VERSION ""

NS_ :

BS_:

BU_: XXX

BO_ 3 NEW_MSG_1: 8 XXX
 SG_ STEERING_ANGLE : 7|32@0- (1,0) [0|4294967295] "" XXX
 SG_ NEW_SIGNAL_1 : 55|8@0+ (1,0) [0|255] "" XXX

BO_ 5 NEW_MSG_2: 8 XXX
 SG_ BRAKE_POSITION : 23|16@0+ (1,0) [0|65535] "" XXX
 SG_ BRAKE_PRESSED : 0|8@1+ (1,0) [0|17] "" XXX

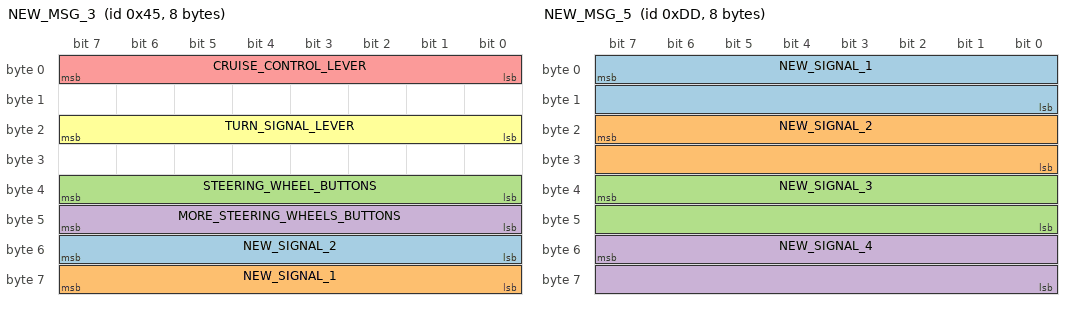
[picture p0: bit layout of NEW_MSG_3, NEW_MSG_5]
BO_ 69 NEW_MSG_3: 8 XXX
 SG_ NEW_SIGNAL_2 : 55|8@0+ (1,0) [0|255] "" XXX
 SG_ NEW_SIGNAL_1 : 63|8@0+ (1,0) [0|255] "" XXX
 SG_ STEERING_WHEEL_BUTTONS : 32|8@1+ (1,0) [0|255] "4 directional, 2 volume control, & 2 phone buttons" XXX
 SG_ MORE_STEERING_WHEELS_BUTTONS : 40|8@1+ (1,0) [0|255] "" XXX
 SG_ CRUISE_CONTROL_LEVER : 7|8@0+ (1,0) [0|255] "" XXX
 SG_ TURN_SIGNAL_LEVER : 16|8@1+ (1,0) [0|255] "" XXX

BO_ 1 NEW_MSG_4: 8 XXX
 SG_ DOOR_LOCK_STATUS : 31|16@0+ (1,0) [0|65535] "" XXX

BO_ 221 NEW_MSG_5: 8 XXX
 SG_ NEW_SIGNAL_1 : 7|16@0+ (1,0) [0|65535] "" XXX
 SG_ NEW_SIGNAL_2 : 23|16@0+ (1,0) [0|65535] "" XXX
 SG_ NEW_SIGNAL_3 : 39|16@0+ (1,0) [0|65535] "" XXX
 SG_ NEW_SIGNAL_4 : 55|16@0+ (1,0) [0|65535] "" XXX

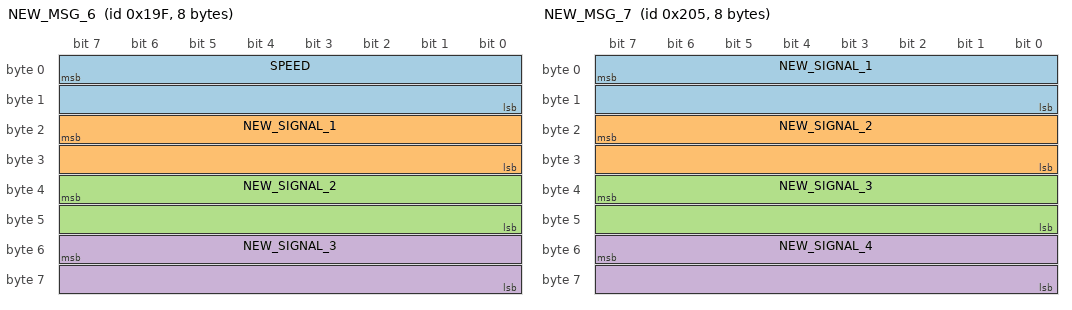
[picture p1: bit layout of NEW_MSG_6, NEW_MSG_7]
BO_ 415 NEW_MSG_6: 8 XXX
 SG_ SPEED : 7|16@0+ (1,0) [0|65535] "kph" XXX
 SG_ NEW_SIGNAL_1 : 23|16@0+ (1,0) [0|65535] "" XXX
 SG_ NEW_SIGNAL_2 : 39|16@0+ (1,0) [0|65535] "" XXX
 SG_ NEW_SIGNAL_3 : 55|16@0+ (1,0) [0|65535] "" XXX

BO_ 517 NEW_MSG_7: 8 XXX
 SG_ NEW_SIGNAL_1 : 7|16@0+ (1,0) [0|65535] "" XXX
 SG_ NEW_SIGNAL_2 : 23|16@0+ (1,0) [0|65535] "" XXX
 SG_ NEW_SIGNAL_3 : 39|16@0+ (1,0) [0|65535] "" XXX
 SG_ NEW_SIGNAL_4 : 55|16@0+ (1,0) [0|65535] "" XXX

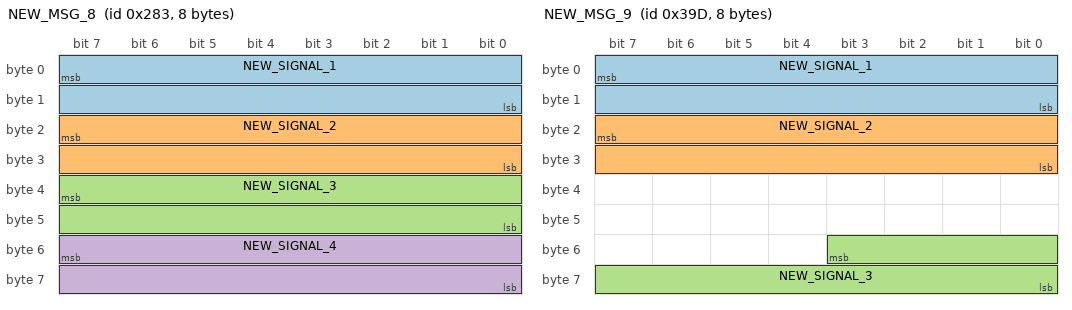
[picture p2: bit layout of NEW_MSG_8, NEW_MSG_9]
BO_ 643 NEW_MSG_8: 8 XXX
 SG_ NEW_SIGNAL_1 : 7|16@0+ (1,0) [0|65535] "" XXX
 SG_ NEW_SIGNAL_2 : 23|16@0+ (1,0) [0|65535] "" XXX
 SG_ NEW_SIGNAL_3 : 39|16@0+ (1,0) [0|65535] "" XXX
 SG_ NEW_SIGNAL_4 : 55|16@0+ (1,0) [0|65535] "" XXX

BO_ 925 NEW_MSG_9: 8 XXX
 SG_ NEW_SIGNAL_1 : 7|16@0+ (1,0) [0|65535] "" XXX
 SG_ NEW_SIGNAL_2 : 23|16@0+ (1,0) [0|65535] "" XXX
 SG_ NEW_SIGNAL_3 : 51|12@0+ (1,0) [0|8191] "" XXX

BO_ 104 NEW_MSG_10: 8 XXX
 SG_ NEW_SIGNAL_1 : 7|8@0+ (1,0) [0|255] "" XXX

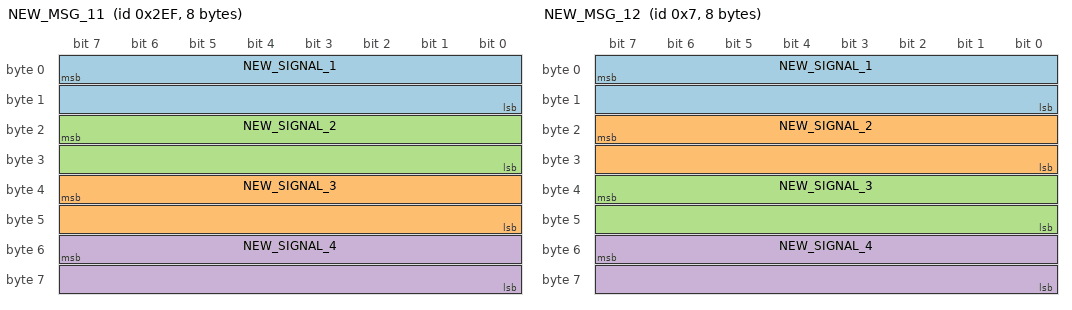
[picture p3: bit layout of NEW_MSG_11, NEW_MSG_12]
BO_ 751 NEW_MSG_11: 8 XXX
 SG_ NEW_SIGNAL_1 : 7|16@0+ (1,0) [0|65535] "" XXX
 SG_ NEW_SIGNAL_3 : 39|16@0+ (1,0) [0|65535] "" XXX
 SG_ NEW_SIGNAL_2 : 23|16@0+ (1,0) [0|65535] "" XXX
 SG_ NEW_SIGNAL_4 : 55|16@0+ (1,0) [0|65535] "" XXX

BO_ 7 NEW_MSG_12: 8 XXX
 SG_ NEW_SIGNAL_1 : 7|16@0+ (1,0) [0|65535] "" XXX
 SG_ NEW_SIGNAL_2 : 23|16@0+ (1,0) [0|65535] "" XXX
 SG_ NEW_SIGNAL_3 : 39|16@0+ (1,0) [0|65535] "" XXX
 SG_ NEW_SIGNAL_4 : 55|16@0+ (1,0) [0|65535] "" XXX

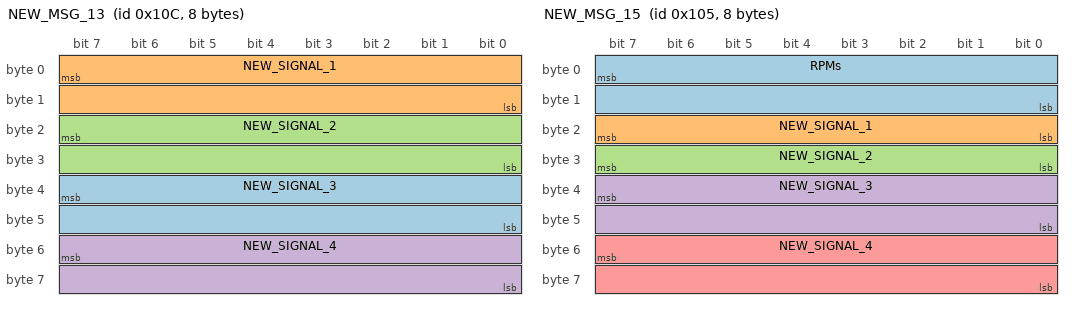
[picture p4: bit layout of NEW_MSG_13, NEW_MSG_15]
BO_ 268 NEW_MSG_13: 8 XXX
 SG_ NEW_SIGNAL_3 : 39|16@0+ (1,0) [0|65535] "" XXX
 SG_ NEW_SIGNAL_1 : 7|16@0+ (1,0) [0|65535] "" XXX
 SG_ NEW_SIGNAL_2 : 23|16@0+ (1,0) [0|65535] "" XXX
 SG_ NEW_SIGNAL_4 : 55|16@0+ (1,0) [0|65535] "" XXX

BO_ 115 NEW_MSG_14: 8 XXX
 SG_ NEW_SIGNAL_1 : 7|8@0+ (1,0) [0|255] "" XXX
 SG_ NEW_SIGNAL_2 : 15|8@0+ (1,0) [0|255] "" XXX
 SG_ NEW_SIGNAL_3 : 48|19@1- (1,0) [0|65535] "" XXX
 SG_ NEW_SIGNAL_4 : 23|16@0+ (1,0) [0|65535] "" XXX
 SG_ NEW_SIGNAL_5 : 39|16@0+ (1,0) [0|65535] "" XXX

BO_ 261 NEW_MSG_15: 8 XXX
 SG_ RPMs : 7|16@0+ (1,0) [0|65535] "" XXX
 SG_ NEW_SIGNAL_1 : 23|8@0+ (1,0) [0|255] "" XXX
 SG_ NEW_SIGNAL_2 : 31|8@0+ (1,0) [0|255] "" XXX
 SG_ NEW_SIGNAL_3 : 39|16@0+ (1,0) [0|65535] "" XXX
 SG_ NEW_SIGNAL_4 : 55|16@0+ (1,0) [0|65535] "" XXX

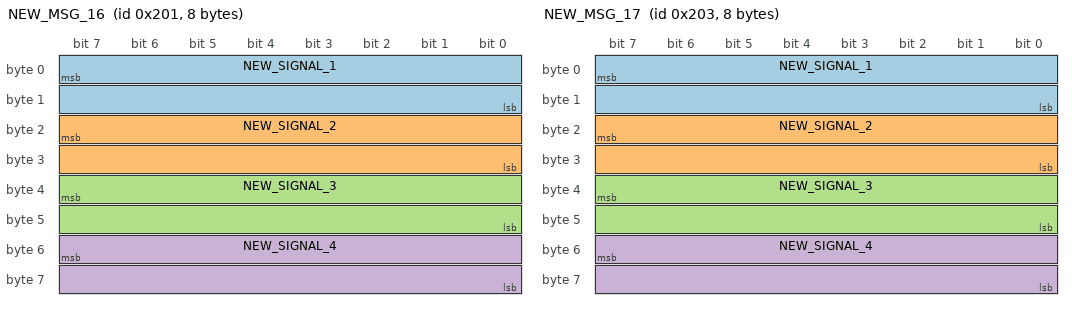
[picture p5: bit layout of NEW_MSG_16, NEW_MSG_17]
BO_ 513 NEW_MSG_16: 8 XXX
 SG_ NEW_SIGNAL_1 : 7|16@0+ (1,0) [0|65535] "" XXX
 SG_ NEW_SIGNAL_2 : 23|16@0+ (1,0) [0|65535] "" XXX
 SG_ NEW_SIGNAL_3 : 39|16@0+ (1,0) [0|65535] "" XXX
 SG_ NEW_SIGNAL_4 : 55|16@0+ (1,0) [0|65535] "" XXX

BO_ 515 NEW_MSG_17: 8 XXX
 SG_ NEW_SIGNAL_1 : 7|16@0+ (1,0) [0|65535] "" XXX
 SG_ NEW_SIGNAL_2 : 23|16@0+ (1,0) [0|65535] "" XXX
 SG_ NEW_SIGNAL_3 : 39|16@0+ (1,0) [0|65535] "" XXX
 SG_ NEW_SIGNAL_4 : 55|16@0+ (1,0) [0|65535] "" XXX

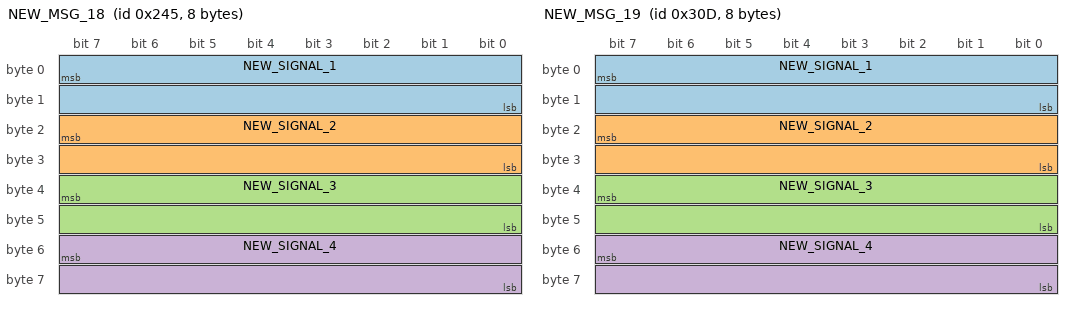
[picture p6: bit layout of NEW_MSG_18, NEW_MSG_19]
BO_ 581 NEW_MSG_18: 8 XXX
 SG_ NEW_SIGNAL_1 : 7|16@0+ (1,0) [0|65535] "" XXX
 SG_ NEW_SIGNAL_2 : 23|16@0+ (1,0) [0|65535] "" XXX
 SG_ NEW_SIGNAL_3 : 39|16@0+ (1,0) [0|65535] "" XXX
 SG_ NEW_SIGNAL_4 : 55|16@0+ (1,0) [0|65535] "" XXX

BO_ 781 NEW_MSG_19: 8 XXX
 SG_ NEW_SIGNAL_1 : 7|16@0+ (1,0) [0|65535] "" XXX
 SG_ NEW_SIGNAL_2 : 23|16@0+ (1,0) [0|65535] "" XXX
 SG_ NEW_SIGNAL_3 : 39|16@0+ (1,0) [0|65535] "" XXX
 SG_ NEW_SIGNAL_4 : 55|16@0+ (1,0) [0|65535] "" XXX

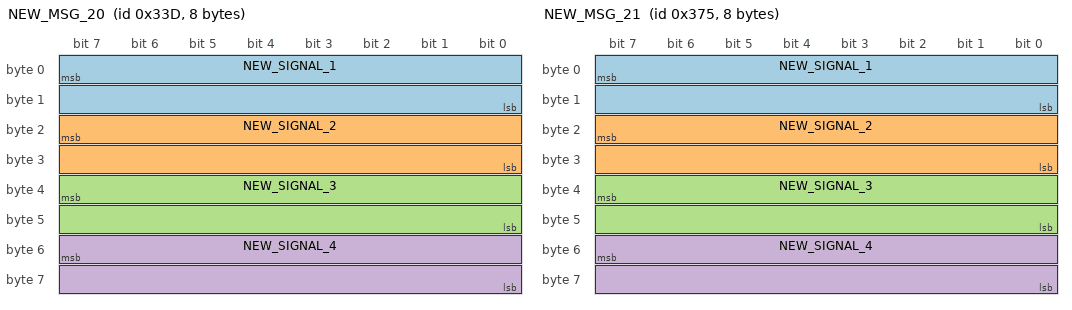
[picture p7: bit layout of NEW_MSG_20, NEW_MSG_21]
BO_ 829 NEW_MSG_20: 8 XXX
 SG_ NEW_SIGNAL_1 : 7|16@0+ (1,0) [0|65535] "" XXX
 SG_ NEW_SIGNAL_2 : 23|16@0+ (1,0) [0|65535] "" XXX
 SG_ NEW_SIGNAL_3 : 39|16@0+ (1,0) [0|65535] "" XXX
 SG_ NEW_SIGNAL_4 : 55|16@0+ (1,0) [0|65535] "" XXX

BO_ 885 NEW_MSG_21: 8 XXX
 SG_ NEW_SIGNAL_1 : 7|16@0+ (1,0) [0|65535] "" XXX
 SG_ NEW_SIGNAL_2 : 23|16@0+ (1,0) [0|65535] "" XXX
 SG_ NEW_SIGNAL_3 : 39|16@0+ (1,0) [0|65535] "" XXX
 SG_ NEW_SIGNAL_4 : 55|16@0+ (1,0) [0|65535] "" XXX

CM_ SG_ 5 BRAKE_PRESSED "appears to be boolean (brake pressed)";
CM_ SG_ 69 MORE_STEERING_WHEELS_BUTTONS "back, ok, voice assistance, and mute buttons";
CM_ SG_ 69 CRUISE_CONTROL_LEVER "Could be correct";
CM_ SG_ 69 TURN_SIGNAL_LEVER "ok, 1 = left, 2 = right";
CM_ SG_ 415 SPEED "Seems smoothened - probably what you see in the dash";
CM_ SG_ 751 NEW_SIGNAL_2 "Was 0 when stopped";
CM_ SG_ 268 NEW_SIGNAL_1 "0 when stopped";
CM_ SG_ 268 NEW_SIGNAL_2 "0 when stopped";
CM_ SG_ 115 NEW_SIGNAL_2 "0 when stopped";
CM_ SG_ 261 RPMs "Likely/to be checked";
